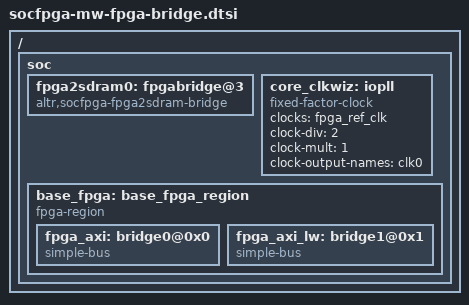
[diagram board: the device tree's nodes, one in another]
/{
	soc{

		fpga2sdram0: fpgabridge@3 {
			compatible = "altr,socfpga-fpga2sdram-bridge";
		};

		core_clkwiz: iopll {
			compatible = "fixed-factor-clock";
			clocks = <&fpga_ref_clk>;
			#clock-cells = <1>;
			clock-div = <2>;
			clock-mult = <1>;
			clock-output-names = "clk0";
		};

		base_fpga: base_fpga_region {

			compatible = "fpga-region", "simple-bus";
			
			ranges =	<0x0 0x0 0xc0000000 0x20000000>,
						<0x1 0x0 0xff200000 0x00200000>;
			#size-cells = <0x1>;
			#address-cells = <0x2>;
			
			fpga_axi: bridge0@0x0 {
				compatible = "simple-bus";
				#size-cells = <0x1>;
				#address-cells = <0x1>;
				ranges = <0x0 0x0 0x0 0x20000000>;
			};

			fpga_axi_lw: bridge1@0x1 {
				compatible = "simple-bus";
				#size-cells = <0x1>;
				#address-cells = <0x1>;
				ranges = <0x0 0x1 0x0 0x00200000>;
			};	   
		};
	};
};
